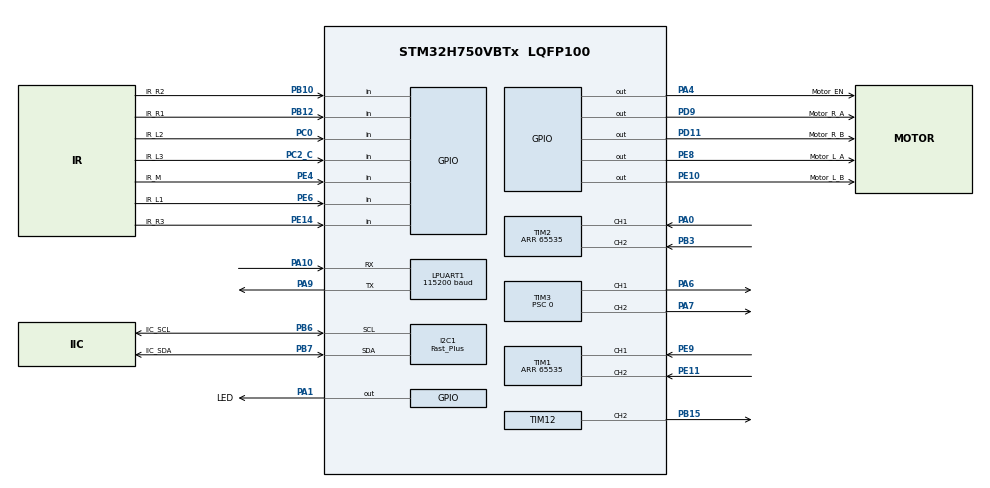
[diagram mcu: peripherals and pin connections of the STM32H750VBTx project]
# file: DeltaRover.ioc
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CORTEX_M7.default_mode_Activation=1
I2C1.I2C_Speed_Mode=I2C_Fast_Plus
I2C1.Timing=0x00100515
LPUART1.BaudRate=115200
Mcu.Family=STM32H7
Mcu.Name=STM32H750VBTx
Mcu.Package=LQFP100
NVIC.LPUART1_IRQn=true\:0\:0\:true\:false\:true\:true\:true\:true
NVIC.PriorityGroup=NVIC_PRIORITYGROUP_4
NVIC.RCC_IRQn=true\:0\:0\:true\:false\:true\:true\:false\:true
NVIC.TIM6_DAC_IRQn=true\:0\:0\:true\:false\:true\:true\:true\:true
NVIC.TIM8_TRG_COM_TIM14_IRQn=true\:0\:0\:true\:false\:true\:true\:true\:true
NVIC.TIM8_UP_TIM13_IRQn=true\:0\:0\:true\:false\:true\:true\:true\:true
PA0.Signal=S_TIM2_CH1_ETR
PA1.GPIO_Label=LED
PA1.Signal=GPIO_Output
PA10.Mode=Asynchronous
PA10.Signal=LPUART1_RX
PA13\ (JTMS/SWDIO).Mode=Serial_Wire
PA13\ (JTMS/SWDIO).Signal=DEBUG_JTMS-SWDIO
PA14\ (JTCK/SWCLK).Mode=Serial_Wire
PA14\ (JTCK/SWCLK).Signal=DEBUG_JTCK-SWCLK
PA4.GPIO_Label=Motor_EN
PA4.Signal=GPIO_Output
PA6.Signal=S_TIM3_CH1
PA7.Signal=S_TIM3_CH2
PA9.Mode=Asynchronous
PA9.Signal=LPUART1_TX
PB10.GPIO_Label=IR_R2
PB10.Signal=GPIO_Input
PB12.GPIO_Label=IR_R1
PB12.Signal=GPIO_Input
PB15.Signal=S_TIM12_CH2
PB3\ (JTDO/TRACESWO).Signal=S_TIM2_CH2
PB6.GPIO_Label=IIC_SCL
PB6.GPIO_Speed=GPIO_SPEED_FREQ_VERY_HIGH
PB6.Mode=I2C
PB6.Signal=I2C1_SCL
PB7.GPIO_Label=IIC_SDA
PB7.GPIO_Speed=GPIO_SPEED_FREQ_VERY_HIGH
PB7.Mode=I2C
PB7.Signal=I2C1_SDA
PC0.GPIO_Label=IR_L2
PC0.Signal=GPIO_Input
PC14-OSC32_IN\ (OSC32_IN).Mode=LSE-External-Oscillator
PC14-OSC32_IN\ (OSC32_IN).Signal=RCC_OSC32_IN
PC15-OSC32_OUT\ (OSC32_OUT).Mode=LSE-External-Oscillator
PC15-OSC32_OUT\ (OSC32_OUT).Signal=RCC_OSC32_OUT
PC2_C.GPIO_Label=IR_L3
PC2_C.Signal=GPIO_Input
PD11.GPIO_Label=Motor_R_B
PD11.Signal=GPIO_Output
PD9.GPIO_Label=Motor_R_A
PD9.Signal=GPIO_Output
PE10.GPIO_Label=Motor_L_B
PE10.Signal=GPIO_Output
PE11.Signal=S_TIM1_CH2
PE14.GPIO_Label=IR_R3
PE14.Signal=GPIO_Input
PE4.GPIO_Label=IR_M
PE4.Signal=GPIO_Input
PE6.GPIO_Label=IR_L1
PE6.Signal=GPIO_Input
PE8.GPIO_Label=Motor_L_A
PE8.Signal=GPIO_Output
PE9.Signal=S_TIM1_CH1
PH0-OSC_IN\ (PH0).Mode=HSE-External-Oscillator
PH0-OSC_IN\ (PH0).Signal=RCC_OSC_IN
PH1-OSC_OUT\ (PH1).Mode=HSE-External-Oscillator
PH1-OSC_OUT\ (PH1).Signal=RCC_OSC_OUT
ProjectManager.HeapSize=0x200
ProjectManager.StackSize=0x400
ProjectManager.TargetToolchain=CMake
RCC.ADCFreq_Value=50390625
RCC.APB1Freq_Value=36000000
RCC.APB2Freq_Value=72000000
RCC.APB3Freq_Value=36000000
RCC.APB4Freq_Value=72000000
RCC.CortexFreq_Value=72000000
RCC.D1PPRE=RCC_APB3_DIV2
RCC.D2PPRE1=RCC_APB1_DIV2
RCC.DIVM1=5
RCC.DIVN1=144
RCC.DIVP1=10
RCC.DIVR1=4
RCC.EnbaleCSS=true
RCC.HCLKFreq_Value=72000000
RCC.PLL2FRACN=0
RCC.PLL3FRACN=0
RCC.PLLFRACN=0
RCC.PLLSourceVirtual=RCC_PLLSOURCE_HSE
RCC.SYSCLKFreq_VALUE=72000000
RCC.SYSCLKSource=RCC_SYSCLKSOURCE_PLLCLK
RCC.USBFreq_Value=360000000
SH.S_TIM12_CH2.0=TIM12_CH2,PWM Generation2 CH2
SH.S_TIM1_CH1.0=TIM1_CH1,Encoder_Interface
SH.S_TIM1_CH2.0=TIM1_CH2,Encoder_Interface
SH.S_TIM2_CH1_ETR.0=TIM2_CH1,Encoder_Interface
SH.S_TIM2_CH2.0=TIM2_CH2,Encoder_Interface
SH.S_TIM3_CH1.0=TIM3_CH1,PWM Generation1 CH1
SH.S_TIM3_CH2.0=TIM3_CH2,PWM Generation2 CH2
TIM1.EncoderMode=TIM_ENCODERMODE_TI12
TIM1.IC1Filter=0xf
TIM1.IC2Filter=0xf
TIM1.Period=65535
TIM12.AutoReloadPreload=TIM_AUTORELOAD_PRELOAD_ENABLE
TIM12.Channel-PWM\ Generation2\ CH2=TIM_CHANNEL_2
TIM12.Period=1999
TIM12.Prescaler=71
TIM12.Pulse-PWM\ Generation2\ CH2=1000
TIM13.AutoReloadPreload=TIM_AUTORELOAD_PRELOAD_ENABLE
TIM13.Period=4999
TIM13.Prescaler=7199
TIM14.AutoReloadPreload=TIM_AUTORELOAD_PRELOAD_ENABLE
TIM14.Period=99
TIM14.Prescaler=7199
TIM2.AutoReloadPreload=TIM_AUTORELOAD_PRELOAD_ENABLE
TIM2.EncoderMode=TIM_ENCODERMODE_TI12
TIM2.IC1Filter=0xf
TIM2.IC2Filter=0xf
TIM2.Period=65535
TIM3.AutoReloadPreload=TIM_AUTORELOAD_PRELOAD_ENABLE
TIM3.Channel-PWM\ Generation1\ CH1=TIM_CHANNEL_1
TIM3.Channel-PWM\ Generation2\ CH2=TIM_CHANNEL_2
TIM3.Period=3599
TIM3.Prescaler=0
TIM6.AutoReloadPreload=TIM_AUTORELOAD_PRELOAD_ENABLE
TIM6.Period=499
TIM6.Prescaler=7199
VP_MEMORYMAP_VS_MEMORYMAP.Mode=CurAppReg
VP_TIM13_VS_ClockSourceINT.Mode=Enable_Timer
VP_TIM14_VS_ClockSourceINT.Mode=Enable_Timer
VP_TIM6_VS_ClockSourceINT.Mode=Enable_Timer
board=custom

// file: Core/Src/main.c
/* USER CODE BEGIN Header */
/**
  ******************************************************************************
  * @file           : main.c
  * @brief          : Main program body
  ******************************************************************************
  * @attention
  *
  * Copyright (c) 2025 STMicroelectronics.
  * All rights reserved.
  *
  * This software is licensed under terms that can be found in the LICENSE file
  * in the root directory of this software component.
  * If no LICENSE file comes with this software, it is provided AS-IS.
  *
  ******************************************************************************
  */
/* USER CODE END Header */
#include "main.h"
#include "i2c.h"
#include "usart.h"
#include "memorymap.h"
#include "tim.h"
#include "gpio.h"

/* USER CODE BEGIN Includes */
#include <string.h>
#include "../../Hardware/sys_info/sys_info.h"
/* USER CODE END Includes */

void SystemClock_Config(void);
static void MPU_Config(void);

int main(void)
{

  /* MPU Configuration--------------------------------------------------------*/
  MPU_Config();

  /* MCU Configuration--------------------------------------------------------*/

  /* Reset of all peripherals, Initializes the Flash interface and the Systick. */
  HAL_Init();

  /* Configure the system clock */
  SystemClock_Config();

  /* Initialize all configured peripherals */
  MX_GPIO_Init();
  MX_TIM1_Init();
  MX_LPUART1_UART_Init();
  MX_TIM2_Init();
  MX_TIM6_Init();
  MX_I2C1_Init();
  MX_TIM12_Init();
  MX_TIM3_Init();
  MX_TIM13_Init();
  MX_TIM14_Init();
  /* USER CODE BEGIN 2 */
  sys_init();
  ir_update();
  /* USER CODE END 2 */

  /* Infinite loop */
  /* USER CODE BEGIN WHILE */
    while (1) {
      sys_info_update();
      HAL_Delay(30);
    /* USER CODE END WHILE */

    }
}

void SystemClock_Config(void)
{
  RCC_OscInitTypeDef RCC_OscInitStruct = {0};
  RCC_ClkInitTypeDef RCC_ClkInitStruct = {0};

  /** Supply configuration update enable
  */
  HAL_PWREx_ConfigSupply(PWR_LDO_SUPPLY);

  /** Configure the main internal regulator output voltage
  */
  __HAL_PWR_VOLTAGESCALING_CONFIG(PWR_REGULATOR_VOLTAGE_SCALE3);

  while(!__HAL_PWR_GET_FLAG(PWR_FLAG_VOSRDY)) {}

  /** Initializes the RCC Oscillators according to the specified parameters
  * in the RCC_OscInitTypeDef structure.
  */
  RCC_OscInitStruct.OscillatorType = RCC_OSCILLATORTYPE_HSE;
  RCC_OscInitStruct.HSEState = RCC_HSE_ON;
  RCC_OscInitStruct.PLL.PLLState = RCC_PLL_ON;
  RCC_OscInitStruct.PLL.PLLSource = RCC_PLLSOURCE_HSE;
  RCC_OscInitStruct.PLL.PLLM = 5;
  RCC_OscInitStruct.PLL.PLLN = 144;
  RCC_OscInitStruct.PLL.PLLP = 10;
  RCC_OscInitStruct.PLL.PLLQ = 2;
  RCC_OscInitStruct.PLL.PLLR = 4;
  RCC_OscInitStruct.PLL.PLLRGE = RCC_PLL1VCIRANGE_2;
  RCC_OscInitStruct.PLL.PLLVCOSEL = RCC_PLL1VCOWIDE;
  RCC_OscInitStruct.PLL.PLLFRACN = 0;
  if (HAL_RCC_OscConfig(&RCC_OscInitStruct) != HAL_OK)
  {
    Error_Handler();
  }

  /** Initializes the CPU, AHB and APB buses clocks
  */
  RCC_ClkInitStruct.ClockType = RCC_CLOCKTYPE_HCLK|RCC_CLOCKTYPE_SYSCLK
                              |RCC_CLOCKTYPE_PCLK1|RCC_CLOCKTYPE_PCLK2
                              |RCC_CLOCKTYPE_D3PCLK1|RCC_CLOCKTYPE_D1PCLK1;
  RCC_ClkInitStruct.SYSCLKSource = RCC_SYSCLKSOURCE_PLLCLK;
  RCC_ClkInitStruct.SYSCLKDivider = RCC_SYSCLK_DIV1;
  RCC_ClkInitStruct.AHBCLKDivider = RCC_HCLK_DIV1;
  RCC_ClkInitStruct.APB3CLKDivider = RCC_APB3_DIV2;
  RCC_ClkInitStruct.APB1CLKDivider = RCC_APB1_DIV2;
  RCC_ClkInitStruct.APB2CLKDivider = RCC_APB2_DIV1;
  RCC_ClkInitStruct.APB4CLKDivider = RCC_APB4_DIV1;

  if (HAL_RCC_ClockConfig(&RCC_ClkInitStruct, FLASH_LATENCY_1) != HAL_OK)
  {
    Error_Handler();
  }

  /** Enables the Clock Security System
  */
  HAL_RCC_EnableCSS();
}

 /* MPU Configuration */

void MPU_Config(void)
{
  MPU_Region_InitTypeDef MPU_InitStruct = {0};

  /* Disables the MPU */
  HAL_MPU_Disable();

  /** Initializes and configures the Region and the memory to be protected
  */
  MPU_InitStruct.Enable = MPU_REGION_ENABLE;
  MPU_InitStruct.Number = MPU_REGION_NUMBER0;
  MPU_InitStruct.BaseAddress = 0x0;
  MPU_InitStruct.Size = MPU_REGION_SIZE_4GB;
  MPU_InitStruct.SubRegionDisable = 0x87;
  MPU_InitStruct.TypeExtField = MPU_TEX_LEVEL0;
  MPU_InitStruct.AccessPermission = MPU_REGION_NO_ACCESS;
  MPU_InitStruct.DisableExec = MPU_INSTRUCTION_ACCESS_DISABLE;
  MPU_InitStruct.IsShareable = MPU_ACCESS_SHAREABLE;
  MPU_InitStruct.IsCacheable = MPU_ACCESS_NOT_CACHEABLE;
  MPU_InitStruct.IsBufferable = MPU_ACCESS_NOT_BUFFERABLE;

  HAL_MPU_ConfigRegion(&MPU_InitStruct);
  /* Enables the MPU */
  HAL_MPU_Enable(MPU_PRIVILEGED_DEFAULT);

}

void Error_Handler(void)
{
    __disable_irq();
    while (1) {
    }
}
